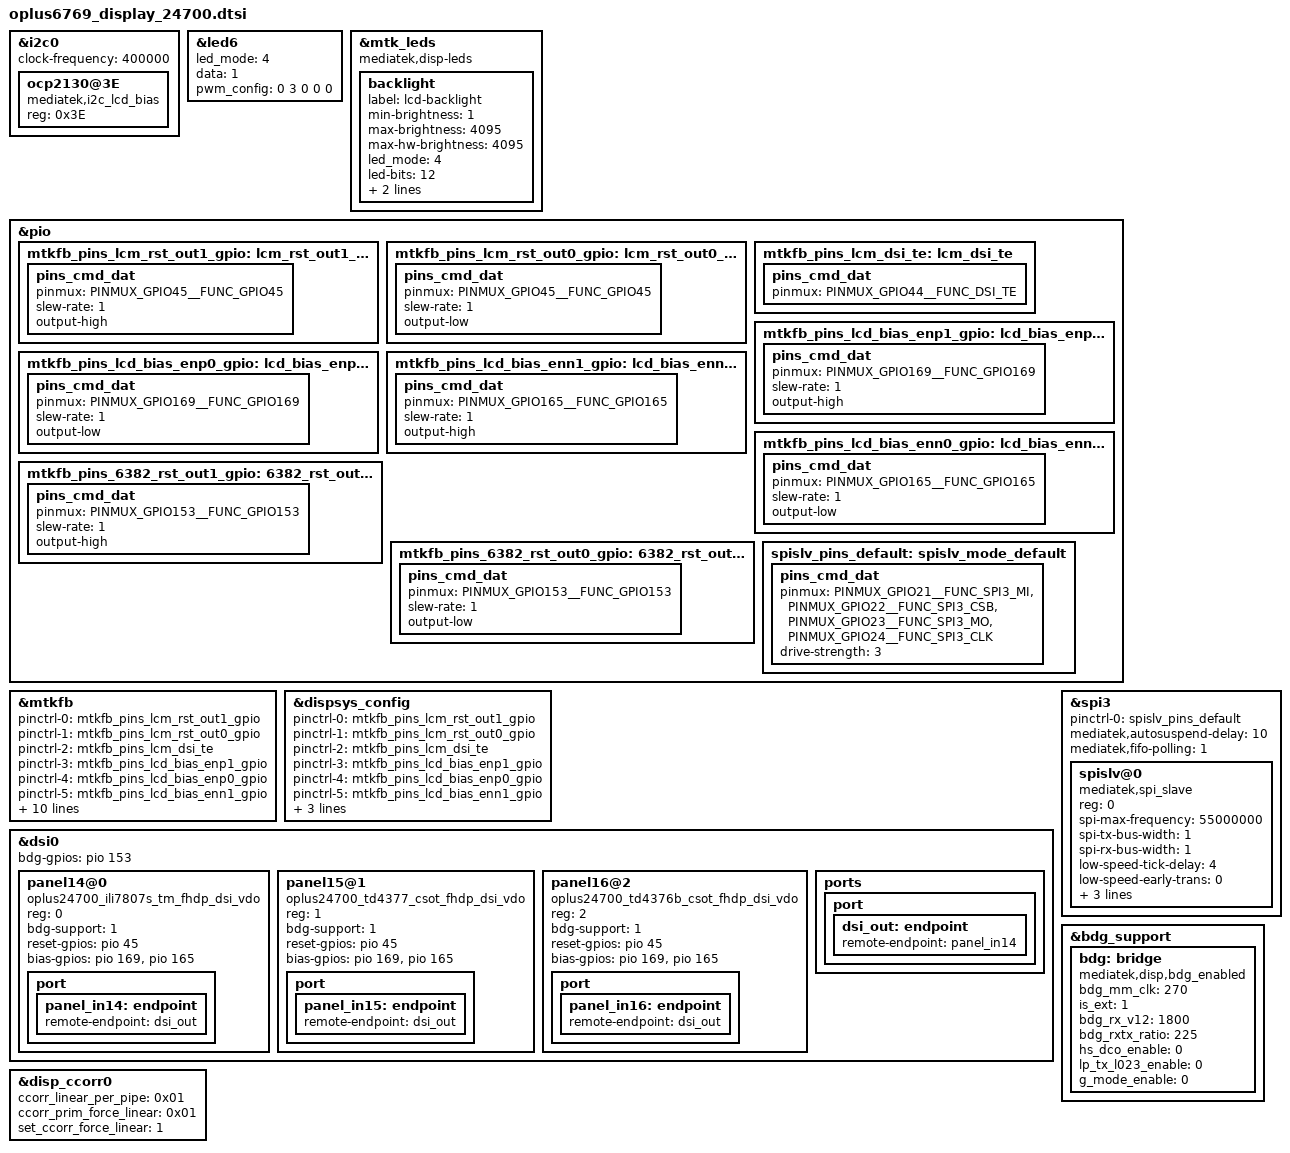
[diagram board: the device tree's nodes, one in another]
// SPDX-License-Identifier: GPL-2.0-only
/*
* Copyright (C) 2020-2021 Oplus. All rights reserved.
*/

/*
 * Add for display bringup
 */

/* lcm_bias:i2c0 */
&i2c0 {
	clock-frequency = <400000>;

	ocp2130@3E {
		compatible = "mediatek,i2c_lcd_bias";
		reg = <0x3E>;
		status = "okay";
	};
};

&led6 {
	led_mode = <4>;
	data = <1>;
	pwm_config = <0 3 0 0 0>;
};
&mtk_leds {
	compatible = "mediatek,disp-leds";

	backlight {
		label = "lcd-backlight";
		min-brightness = <1>;
		max-brightness = <4095>;
		max-hw-brightness = <4095>;
		led_mode = <4>;
		led-bits = <12>;
		trans-bits = <12>;
		default-state = "on";
	};
};
/* DISPSYS GPIO standardization */
&pio {
	mtkfb_pins_lcm_rst_out1_gpio: lcm_rst_out1_gpio {
		pins_cmd_dat {
			pinmux = <PINMUX_GPIO45__FUNC_GPIO45>;
			slew-rate = <1>;
			output-high;
		};
	};

	mtkfb_pins_lcm_rst_out0_gpio: lcm_rst_out0_gpio {
		pins_cmd_dat {
			pinmux = <PINMUX_GPIO45__FUNC_GPIO45>;
			slew-rate = <1>;
			output-low;
		};
	};

	mtkfb_pins_lcm_dsi_te: lcm_dsi_te {
		pins_cmd_dat {
			pinmux = <PINMUX_GPIO44__FUNC_DSI_TE>;
		};
	};

	mtkfb_pins_lcd_bias_enp1_gpio: lcd_bias_enp1_gpio {
		pins_cmd_dat {
			pinmux = <PINMUX_GPIO169__FUNC_GPIO169>;
			slew-rate = <1>;
			output-high;
		};
	};

	mtkfb_pins_lcd_bias_enp0_gpio: lcd_bias_enp0_gpio {
		pins_cmd_dat {
			pinmux = <PINMUX_GPIO169__FUNC_GPIO169>;
			slew-rate = <1>;
			output-low;
		};
	};
	mtkfb_pins_lcd_bias_enn1_gpio: lcd_bias_enn1_gpio {
		pins_cmd_dat {
			pinmux = <PINMUX_GPIO165__FUNC_GPIO165>;
			slew-rate = <1>;
			output-high;
		};
	};

	mtkfb_pins_lcd_bias_enn0_gpio: lcd_bias_enn0_gpio {
		pins_cmd_dat {
			pinmux = <PINMUX_GPIO165__FUNC_GPIO165>;
			slew-rate = <1>;
			output-low;
		};
	};
	mtkfb_pins_6382_rst_out1_gpio: 6382_rst_out1_gpio {
		pins_cmd_dat {
			pinmux = <PINMUX_GPIO153__FUNC_GPIO153>;
			slew-rate = <1>;
			output-high;
		};
	};
	mtkfb_pins_6382_rst_out0_gpio: 6382_rst_out0_gpio {
		pins_cmd_dat {
			pinmux = <PINMUX_GPIO153__FUNC_GPIO153>;
			slew-rate = <1>;
			output-low;
		};
	};
	//mtkfb_pins_6382_pmic_26m_ctl0: 6382-pmic-26m-gpio-ctl0 {
	//	pins_cmd_dat {
	//		pinmux = <PINMUX_GPIO148__FUNC_SRCLKENAI0>;
	//		input-enable;
	//		slew-rate = <0>;
	//		bias-pull-down;
	//	};
	//};
	//mtkfb_pins_6382_pmic_26m_ctl1: 6382-pmic-26m-gpio-ctl1 {
	//	pins_cmd_dat {
	//		pinmux = <PINMUX_GPIO148__FUNC_SRCLKENAI0>;
	//		input-enable;
	//		slew-rate = <0>;
	//		bias-pull-up;
	//	};
	//};
};

&mtkfb {
	pinctrl-names =
		"lcm_rst_out1_gpio", "lcm_rst_out0_gpio",
		"mode_te_te", "lcd_bias_enp1_gpio",
		"lcd_bias_enp0_gpio",
		"lcd_bias_enn1_gpio",
		"lcd_bias_enn0_gpio",
		"6382_rst_out1_gpio",
		"6382_rst_out0_gpio";
		//"6382-pmic-26m-gpio-ctl0";
	pinctrl-0 = <&mtkfb_pins_lcm_rst_out1_gpio>;
	pinctrl-1 = <&mtkfb_pins_lcm_rst_out0_gpio>;
	pinctrl-2 = <&mtkfb_pins_lcm_dsi_te>;
	pinctrl-3 = <&mtkfb_pins_lcd_bias_enp1_gpio>;
	pinctrl-4 = <&mtkfb_pins_lcd_bias_enp0_gpio>;
	pinctrl-5 = <&mtkfb_pins_lcd_bias_enn1_gpio>;
	pinctrl-6 = <&mtkfb_pins_lcd_bias_enn0_gpio>;
	pinctrl-7 = <&mtkfb_pins_6382_rst_out1_gpio>;
	pinctrl-8 = <&mtkfb_pins_6382_rst_out0_gpio>;
	//pinctrl-9 = <&mtkfb_pins_6382_pmic_26m_ctl0>;
	status = "okay";

	oplus_display_twelvebits_support;
	oplus_display_cabc_support;
	oplus_display_panel_cabc_support;
	oplus_display_panel_cabc_power_saving_support;
	oplus_display_cabc_cmdq_support;
	oplus_display_normal_max_brightness = <4095>;
	oplus_display_mt6382_support;
};

&dispsys_config {
	pinctrl-names =
		"lcm_rst_out1_gpio", "lcm_rst_out0_gpio",
		"mode_te_te",
        "lcd_bias_enp1_gpio", "lcd_bias_enp0_gpio",
        "lcd_bias_enn1_gpio", "lcd_bias_enn0_gpio",
		"6382_rst_out1_gpio", "6382_rst_out0_gpio";
		//"6382-pmic-26m-gpio-ctl0";
	pinctrl-0 = <&mtkfb_pins_lcm_rst_out1_gpio>;
	pinctrl-1 = <&mtkfb_pins_lcm_rst_out0_gpio>;
	pinctrl-2 = <&mtkfb_pins_lcm_dsi_te>;
	pinctrl-3 = <&mtkfb_pins_lcd_bias_enp1_gpio>;
	pinctrl-4 = <&mtkfb_pins_lcd_bias_enp0_gpio>;
	pinctrl-5 = <&mtkfb_pins_lcd_bias_enn1_gpio>;
	pinctrl-6 = <&mtkfb_pins_lcd_bias_enn0_gpio>;
	pinctrl-7 = <&mtkfb_pins_6382_rst_out1_gpio>;
	pinctrl-8 = <&mtkfb_pins_6382_rst_out0_gpio>;
	//pinctrl-9 = <&mtkfb_pins_6382_pmic_26m_ctl0>;
	status = "okay";
};

&dsi0 {
	status = "okay";
	#address-cells = <1>;
	#size-cells = <0>;
	bdg-gpios = <&pio 153 0>;
	//panel1@0 {
	//	compatible = "oplus23703_ili9883c_hkc_hdp_dsi_vdo";
	//	reg = <0>;
	//	reset-gpios = <&pio 45 0>;
	//	bias-gpios = <&pio 169 0>,<&pio 165 0>;
	//	pinctrl-names = "default";
	//	port {
	//		panel_in1: endpoint {
	//			remote-endpoint = <&dsi_out>;
	//		};
	//	};
	//};
	//panel2@1 {
	//	compatible = "oplus23703_ili9883c_dj_hdp_dsi_vdo";
	//	reg = <1>;
	//	reset-gpios = <&pio 45 0>;
	//	bias-gpios = <&pio 169 0>,<&pio 165 0>;
	//	pinctrl-names = "default";
	//	port {
	//		panel_in2: endpoint {
	//			remote-endpoint = <&dsi_out>;
	//		};
	//	};
	//};
	panel14@0 {
		compatible = "oplus24700_ili7807s_tm_fhdp_dsi_vdo";
		reg = <0>;
		bdg-support = <1>;
		reset-gpios = <&pio 45 0>;
		bias-gpios = <&pio 169 0>,<&pio 165 0>;
		pinctrl-names = "default";
		port {
			panel_in14: endpoint {
				remote-endpoint = <&dsi_out>;
			};
		};
	};
	panel15@1 {
		compatible = "oplus24700_td4377_csot_fhdp_dsi_vdo";
		reg = <1>;
		bdg-support = <1>;
		reset-gpios = <&pio 45 0>;
		bias-gpios = <&pio 169 0>,<&pio 165 0>;
		pinctrl-names = "default";
		port {
			panel_in15: endpoint {
				remote-endpoint = <&dsi_out>;
			};
		};
	};
	panel16@2 {
		compatible = "oplus24700_td4376b_csot_fhdp_dsi_vdo";
		reg = <2>;
		bdg-support = <1>;
		reset-gpios = <&pio 45 0>;
		bias-gpios = <&pio 169 0>,<&pio 165 0>;
		pinctrl-names = "default";
		port {
			panel_in16: endpoint {
				remote-endpoint = <&dsi_out>;
			};
		};
	};
	ports {
		port {
			dsi_out: endpoint {
				remote-endpoint = <&panel_in14>;
			};
		};
	};
};

&spi3 {
	status = "okay";
	#address-cells = <1>;
	#size-cells = <0>;
	pinctrl-names = "default";
	pinctrl-0 = <&spislv_pins_default>;
	mediatek,autosuspend-delay = <10>;
	mediatek,fifo-polling = <1>;

	spislv@0 {
		compatible = "mediatek,spi_slave";
		reg = <0>;
		spi-max-frequency = <55000000>;
		spi-tx-bus-width = <1>;
		spi-rx-bus-width = <1>;
		low-speed-tick-delay = /bits/ 8 <4>;
		low-speed-early-trans = /bits/ 8 <0>;
		high-speed-tick-delay = /bits/ 8 <2>;
		high-speed-early-trans = /bits/ 8 <0>;
		slave-drive-strength = /bits/ 8 <3>;
	};
};

&pio {
	spislv_pins_default: spislv_mode_default {
		pins_cmd_dat {
			pinmux = <PINMUX_GPIO21__FUNC_SPI3_MI>,
					<PINMUX_GPIO22__FUNC_SPI3_CSB>,
					<PINMUX_GPIO23__FUNC_SPI3_MO>,
					<PINMUX_GPIO24__FUNC_SPI3_CLK>;
					 drive-strength = <3>;
				};
	};
};

&bdg_support {
	bdg: bridge {
		compatible = "mediatek,disp,bdg_enabled";
        bdg_mm_clk = <270>;
	is_ext = <1>;
        bdg_rx_v12 = <1800>;
        bdg_rxtx_ratio = <225>;
        hs_dco_enable = <0>;
        lp_tx_l023_enable = <0>;
        g_mode_enable = <0>;
	};
};

&disp_ccorr0 {
	ccorr_linear_per_pipe = <0x01>;
	ccorr_prim_force_linear = <0x01>;
	set_ccorr_force_linear = <1>;
};

/* DISPSYS GPIO standardization end*/
